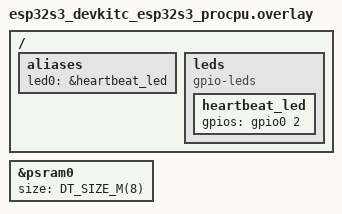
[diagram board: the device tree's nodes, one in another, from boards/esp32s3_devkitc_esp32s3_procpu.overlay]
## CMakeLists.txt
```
cmake_minimum_required(VERSION 3.20.0)

# Issue #71: pick up a local, untracked wifi_credentials.conf automatically
# if present (copied from wifi_credentials.conf.example - see
# firmware/README.md) - must happen before find_package(Zephyr ...) below,
# since that's where Kconfig fragments get collected. Never committed (see
# firmware/.gitignore); a clean checkout with no local file builds against
# this app's plain Kconfig defaults instead.
if(EXISTS "${CMAKE_CURRENT_SOURCE_DIR}/wifi_credentials.conf")
  set(EXTRA_CONF_FILE "${CMAKE_CURRENT_SOURCE_DIR}/wifi_credentials.conf")
endif()

find_package(Zephyr REQUIRED HINTS $ENV{ZEPHYR_BASE})
project(qc_bridge_firmware)

# ETL (https://github.com/ETLCPP/etl) - fixed-capacity containers, no heap
# allocation. See CODING_STANDARDS.md's Firmware/Memory & containers section.
include(FetchContent)
FetchContent_Declare(
  etl
  GIT_REPOSITORY https://github.com/ETLCPP/etl.git
  GIT_TAG        20.49.0
)
FetchContent_MakeAvailable(etl)

# miniz (https://github.com/richgel999/miniz) - issue #6's gzip detection
# for compressed message payloads, see ADR 0005. We want only its
# low-level inflate function (tinfl_decompress), not the deflate/zip-
# archive/zlib-wrapper code the rest of miniz also provides, and not its
# own CMakeLists.txt (which builds all of that as one target and calls
# project() in a way that doesn't nest cleanly inside a Zephyr app) - so
# this fetches the source tree only (FetchContent_Populate, not
# MakeAvailable: deliberately does not add_subdirectory it) and compiles
# just miniz_tinfl.c ourselves. The MINIZ_NO_* defines below strip the
# declarations miniz.h would otherwise pull in for the parts we're not
# compiling down to nothing. miniz_export.h (normally generated by
# miniz's own CMake via generate_export_header() for a shared-library
# build) is our own trivial stub - see third_party/miniz/miniz_export.h.
FetchContent_Declare(
  miniz
  GIT_REPOSITORY https://github.com/richgel999/miniz.git
  GIT_TAG        3.0.2
)
FetchContent_Populate(miniz)

# subsys/usb/host's own headers (usbh_class.h, usbh_desc.h, ...) aren't part
# of Zephyr's public API and aren't exported by its build - needed by
# usbh_shim.c, which is the only file that includes them. See that file.
zephyr_include_directories(${ZEPHYR_BASE}/subsys/usb/host)

target_sources(app PRIVATE
  src/Main.cpp
  src/usbh_shim.c
  ${miniz_SOURCE_DIR}/miniz_tinfl.c
)
target_include_directories(app PRIVATE
  ${miniz_SOURCE_DIR}
  ${CMAKE_CURRENT_SOURCE_DIR}/third_party/miniz
)
target_compile_definitions(app PRIVATE
  MINIZ_NO_STDIO
  MINIZ_NO_MALLOC
  MINIZ_NO_TIME
  # Not also defining MINIZ_NO_ARCHIVE_WRITING_APIS: miniz.h already
  # implies it from MINIZ_NO_DEFLATE_APIS (and MINIZ_NO_ARCHIVE_APIS
  # implies it a second time) - passing it here too just redefines the
  # same macro and trips a -Wmacro-redefined warning for no benefit.
  MINIZ_NO_DEFLATE_APIS
  MINIZ_NO_ARCHIVE_APIS
  MINIZ_NO_ZLIB_APIS
)
target_link_libraries(app PRIVATE etl::etl)

# Issue #71: links QcWifiWebTransport.hpp's HTTP_SERVICE_DEFINE(qcWebService,
# ...) to its own iterable-section linker fragment (sections-rom.ld) - see
# that file's own comment for why this is required, not optional, wiring.
zephyr_linker_sources(SECTIONS sections-rom.ld)
zephyr_linker_section(NAME http_resource_desc_qcWebService KVMA RAM_REGION GROUP RODATA_REGION)

# Issue #88 / ADR 0011: gzips web/ui into a generated header of static HTTP
# resources - see cmake/EmbedWebAssets.cmake for what this wires up.
# QcWifiWebTransport.hpp #includes the result unconditionally.
include(${CMAKE_CURRENT_SOURCE_DIR}/cmake/EmbedWebAssets.cmake)
qc_embed_web_assets(app)
```

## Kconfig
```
# Issue #71: Wi-Fi mode/credentials, chosen at build time. Mode itself
# reuses Zephyr's own generic choice (drivers/wifi/Kconfig,
# WIFI_USAGE_MODE_AP/STA) rather than inventing a parallel one - that choice
# is already what the NXP Wi-Fi driver keys its own SoftAP/DHCP-server
# defaults off (see ADR 0010). Real credentials belong in a local,
# untracked wifi_credentials.conf (see wifi_credentials.conf.example in
# this directory and firmware/README.md) - never in this file or in
# prj.conf, and never committed.

mainmenu "QC Remote Bridge Firmware"

config QC_WIFI_AP_SSID
	string "Soft AP SSID (CONFIG_WIFI_USAGE_MODE_AP)"
	default "QCRemote"
	depends on WIFI_USAGE_MODE_AP
	help
	  SSID the board advertises when running as its own access point.
	  Override in a local wifi_credentials.conf, not here.

config QC_WIFI_AP_PSK
	string "Soft AP WPA2 passphrase (CONFIG_WIFI_USAGE_MODE_AP)"
	default ""
	depends on WIFI_USAGE_MODE_AP
	help
	  WPA2-PSK passphrase for the board's own access point (8-63
	  characters). Left empty, the AP starts open (no password) - the
	  owner's decision for issue #71 is to set a real passphrase here via
	  a local wifi_credentials.conf whenever that's easy, rather than
	  defaulting to an open network. Never set a real passphrase in this
	  file or in prj.conf.

config QC_WIFI_AP_APP_DHCP_SERVER
	bool "Start the AP's address and DHCPv4 server in the app"
	default y if !WIFI_NXP
	depends on WIFI_USAGE_MODE_AP
	select NET_DHCPV4_SERVER
	help
	  The NXP Wi-Fi driver sets the SoftAP's address and runs its own
	  DHCPv4 server (CONFIG_NXP_WIFI_SOFTAP_*), and a second server would
	  collide with it (ADR 0010). Other drivers, such as the ESP32's,
	  leave both to the app - this turns that on, using the address
	  below.

config QC_WIFI_AP_IP_ADDRESS
	string "AP interface IPv4 address"
	default "192.168.4.1"
	depends on QC_WIFI_AP_APP_DHCP_SERVER
	help
	  Also the gateway. The DHCPv4 pool starts 10 addresses above it,
	  matching the 192.168.4.x range the NXP build uses.

config QC_WIFI_AP_NETMASK
	string "AP interface IPv4 netmask"
	default "255.255.255.0"
	depends on QC_WIFI_AP_APP_DHCP_SERVER

config QC_WIFI_STA_SSID
	string "Network SSID to join (CONFIG_WIFI_USAGE_MODE_STA)"
	default ""
	depends on WIFI_USAGE_MODE_STA
	help
	  SSID of the existing Wi-Fi network the board should join. Left
	  empty, the firmware logs a warning and skips connecting rather than
	  attempting to join a blank network - set this in a local
	  wifi_credentials.conf.

config QC_WIFI_STA_PSK
	string "Network WPA2 passphrase (CONFIG_WIFI_USAGE_MODE_STA)"
	default ""
	depends on WIFI_USAGE_MODE_STA
	help
	  WPA2-PSK passphrase for the network above. Set this in a local
	  wifi_credentials.conf - never here or in prj.conf.

config QC_USBH_FORCE_FULL_SPEED
	bool "Force the USB host port to Full Speed (test only)"
	depends on SOC_SERIES_RW6XX
	help
	  Sets PORTSC1.PFSC on the RW61x USB controller, so the port never
	  chirps up to High Speed and the attached device has to run at
	  12 Mbit/s. Lets the RW612 stand in for a Full Speed-only host
	  (ESP32-S3, MAX3421E) - see issue #76. The bit must be set before
	  the device attaches, so plug it in after boot. Leave off in normal
	  builds.

config QC_MESSAGE_CAPACITY
	int "Largest reassembled message, in bytes"
	default 131072
	help
	  Size of the HID reassembly buffer and the dispatcher mailbox, which
	  are kept equal. 128 KiB holds a worst-case fully-named preset folder
	  (ADR 0007). Boards with less internal RAM can lower it at the cost
	  of dropping messages larger than this.

config QC_WIFI_WEB_TICK_INTERVAL_MS
	int "WebSocket tick heartbeat interval, in milliseconds"
	default 5000
	help
	  How often QcWifiWebTransport sends a liveness-only "tick" envelope
	  (issue #75 / ADR 0011) to a connected WebSocket client when nothing
	  else was sent in that window. Without it, an idle rig and a
	  half-open socket after a Wi-Fi drop look identical - silence either
	  way. Matches web/poc/src/store.js's own assumed cadence (same ADR).

source "Kconfig.zephyr"
```

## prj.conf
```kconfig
# C++23, no exceptions/RTTI - see CODING_STANDARDS.md's Firmware section.
CONFIG_CPP=y
CONFIG_STD_CPP23=y
CONFIG_CPP_EXCEPTIONS=n
CONFIG_CPP_RTTI=n

# Zephyr defaults to MINIMAL_LIBCPP (no <span>, no STL) unless asked
# otherwise - not enough for this codebase (std::span, ETL, etc.). Selects
# GLIBCXX_LIBCPP given picolibc + the zephyr/gnu toolchain (lib/cpp/Kconfig).
CONFIG_REQUIRES_FULL_LIBCPP=y

# Heartbeat LED sanity check
CONFIG_GPIO=y

CONFIG_LOG=y
CONFIG_LOG_MODE_IMMEDIATE=y

# USB host [EXPERIMENTAL] - see ADR 0002 for the accepted risk. Enumerates
# the Quad Cortex Mini and claims its vendor HID interface (issue #3). Pulls
# in UHC_DRIVER; the NXP EHCI controller driver auto-selects itself once
# boards/frdm_rw612.overlay enables the usbh devicetree node.
CONFIG_USB_HOST_STACK=y

# Zephyr's own internal `usbh` thread (the same one that runs
# onProbe()/onReportIn(), see UsbHostClass.hpp) defaults to a 1024-byte
# stack (subsys/usb/host/Kconfig's CONFIG_USBH_STACK_SIZE) - a logging call
# added there during issue #8's hardware debugging (since removed, see
# QcSession.hpp's handleMessage()) overflowed it, confirmed via addr2line
# against the faulting PC/LR. With that logging gone for good,
# Zephyr's THREAD_ANALYZER measured this thread's real peak usage on
# hardware at 736 bytes; 1536 keeps that at just under half of budget
# rather than carrying forward the earlier emergency doubling to 2048 now
# that there's a real number to size against.
CONFIG_USBH_STACK_SIZE=1536

# So a future fault dump names the thread involved instead of "(unknown)" -
# this was off during issue #8's hardware debugging, which is also why
# Zephyr's own k_thread_name_set(&usbh_thread_data, "usbh") (usbh_core.c)
# and our own k_thread_name_set() calls (QcSession.hpp) weren't showing up
# in a fault dump either.
CONFIG_THREAD_NAME=y

# Issue #71: Wi-Fi + the web/WebSocket transport test - see ADR 0010.
# CONFIG_WIFI_USAGE_MODE_AP/STA itself (and real SSID/PSK) are chosen in a
# local, untracked wifi_credentials.conf (see wifi_credentials.conf.example
# and firmware/README.md) - everything below is the always-on plumbing
# that choice depends on either way, so it's committed. The Wi-Fi driver
# and its own settings are per board: boards/frdm_rw612.conf (NXP driver,
# which also runs the SoftAP's DHCPv4 server) and
# boards/esp32s3_devkitc_esp32s3_procpu.conf (ESP32 driver; the app runs
# the SoftAP's DHCPv4 server - CONFIG_QC_WIFI_AP_APP_DHCP_SERVER).
CONFIG_WIFI=y
CONFIG_ETH_DRIVER=n

CONFIG_NETWORKING=y
CONFIG_NET_L2_WIFI_MGMT=y
CONFIG_NET_IPV4=y
CONFIG_NET_TCP=y
CONFIG_NET_UDP=y
# STA mode: CONFIG_WIFI_STA_AUTO_DHCPV4 (subsys/net/l2/wifi/Kconfig,
# default y) starts the DHCPv4 client automatically once connected - no
# app code needed. AP mode: hardware testing on ac601b2 found that the NXP
# driver's own CONFIG_NXP_WIFI_SOFTAP_DHCP_SERVER DOES auto-start a
# DHCPv4 server for SoftAP - confirmed against drivers/wifi/nxp/src/
# nxp_wifi_drv.c's WLAN_REASON_UAP_SUCCESS handler, which this firmware's
# own now-removed app-layer DHCPv4 server start was conflicting with
# (-EALREADY, logged as nxp_wifi's "DHCP Server start failed" on
# hardware). CONFIG_NET_DHCPV4_SERVER itself is selected transitively by
# CONFIG_NXP_WIFI_SOFTAP_DHCP_SERVER on the RW612, and by the app's own
# CONFIG_QC_WIFI_AP_APP_DHCP_SERVER on other drivers (both only in AP
# mode) - no need to set it here, and station-only builds never pull it
# in since they have no DHCP server to run.
CONFIG_NET_DHCPV4=y
CONFIG_NET_IF_MAX_IPV4_COUNT=2
CONFIG_NET_CONFIG_AUTO_INIT=n
CONFIG_NET_CONNECTION_MANAGER=y
CONFIG_NET_MGMT=y
CONFIG_NET_MGMT_EVENT=y
# QcWifiWebTransport::onWifiEvent() reads net_mgmt_event_callback::info
# (e.g. the joining/leaving station's MAC in NET_EVENT_WIFI_AP_STA_*) -
# that field only exists when this is enabled.
CONFIG_NET_MGMT_EVENT_INFO=y
CONFIG_NET_MGMT_EVENT_QUEUE_SIZE=10
CONFIG_NET_MGMT_EVENT_STACK_SIZE=4608
# NET_PKT_{RX,TX}_COUNT and the net_buf counts are set with the TCP
# window budget further down - see CONFIG_NET_TCP_MAX_SEND_WINDOW_SIZE.
CONFIG_NET_SOCKETS_SERVICE_STACK_SIZE=4096
CONFIG_NET_TCP_WORKQ_STACK_SIZE=2048
CONFIG_SYSTEM_WORKQUEUE_STACK_SIZE=2048
CONFIG_MAIN_STACK_SIZE=4096

# Issue #71 hardware finding (26bfec1): root cause of the rx_q[0] stack-
# overflow usage fault on page load, in both AP and station mode, with or
# without a Quad Cortex attached - confirmed from source and from this
# build's own zephyr.elf, not our own code. Enabling Wi-Fi here pulls in
# CONFIG_PSA_CRYPTO + CONFIG_MCUX_ELS_PKC (the Wi-Fi driver's own security
# needs); subsys/net/ip/Kconfig.tcp's CONFIG_NET_TCP_ISN_RFC6528 ("depends
# on PSA_WANT_ALG_SHA_256", default y) silently flips on as a result - it's
# off on master today precisely because that dependency isn't met there.
# Once on, every newly-accepted TCP connection's initial sequence number
# (subsys/net/ip/tcp.c's tcp_isn_hash(), called inline during SYN
# processing on net_tc's own "rx_q[N]" thread - confirmed at net_tc.c:421)
# computes a real SHA-256 via psa_hash_compute() -> the hardware-backed
# ELS/PKC driver -> NXP's mcuxCl hash library, instead of master's shallow
# sys_rand32_get() fallback. Measured on this build's zephyr.elf (gcc
# prologue push+sub sp, same per-frame method as every other stack-margin
# table in this firmware): tcp_isn_hash (56 B) -> psa_hash_compute (tail
# call, net 0 B) -> psa_driver_wrapper_hash_compute (40 B) ->
# els_pkc_transparent_hash_compute (32 B) ->
# mcuxClPsaDriver_psa_driver_wrapper_hash_compute (296 B) ->
# mcuxClHash_compute (120 B) -> mcuxClHashModes_Els_oneShot_Sha2 (152 B) ->
# its _FullBlocks/_ProcessData/_Truncated callee (108-240 B depending on
# input length) -> mcuxClHashModes_Els_oneShot_Sha2_Padding (120 B) ->
# mcuxClMemory_copy (80 B, where the fault PC/LR from both hardware runs
# land - 0x18006dba/0x18004db5 on this build) = ~1136 B for this chain
# alone, on top of whatever net_tc/IP/TCP processing it took to reach SYN
# handling in the first place - loading the page's first new TCP
# connection (the fetch and/or the WebSocket upgrade) is what triggers it,
# which is why an empty catalog and no USB device still crash identically.
# CONFIG_NET_RX_STACK_SIZE's own default (1500 B, matching the "1504"
# thread_analyzer budget on hardware) was sized for the pre-Wi-Fi,
# non-cryptographic ISN path and was never going to survive this chain.
# Doubled to a round 3072 B - leaves real headroom (the chain above is the
# deepest path this thread takes; ordinary packet forwarding is far
# shallower) without the much larger jump a "disable the fancy ISN
# instead" workaround would have avoided needing. Unverified on hardware -
# needs a fresh flash to confirm (see firmware/README.md).
CONFIG_NET_RX_STACK_SIZE=3072

# Zephyr's HTTP server [EXPERIMENTAL] + its websocket upgrade path -
# issue #71's "minimal page and a WebSocket" requirement
# (QcWifiWebTransport.hpp). CONFIG_HTTP_SERVER_WEBSOCKET selects
# WEBSOCKET_CLIENT (the same library backs both directions of the
# protocol).
#
# WEBSOCKET_MAX_CONTEXTS=2, matching QcWifiWebTransport's own
# kMaxWsContexts - issue #99 / ADR 0012: one live page, and the newest one
# wins, so a new page's upgrade has to succeed while the old page is still
# connected; the old one is then closed with 4001. Zephyr hands this
# resource's one static data_buffer (g_qcWsDataBuffer) to
# websocket_register() on every upgrade, so both contexts share it (issue
# #75, ADR 0010) - safe only because the transport's worker thread reads
# just the live socket, and starts reading the new one after closing the
# old. See kMaxWsContexts' own comment.
CONFIG_HTTP_SERVER=y
CONFIG_HTTP_SERVER_WEBSOCKET=y
# Eight, after 13 regressed the board (PR #92, third round). 6 for a
# browser's own per-host connection cap + 1 for a transient WebSocket
# upgrade (which holds a slot only until
# handle_http1_to_websocket_upgrade() hands the socket off) + 1 spare.
#
# 13 was sized for two browsers' *parked* connections and made hardware
# strictly worse: Chrome went from loading fine to hanging, with one
# module eventually RST mid-response after 45s. Parked idle connections
# cost a slot but no network buffers; connections being *served* cost
# both, and the server accepts up to this many, so this number also caps
# how many sends can be in flight at once - which is what the TCP window
# budget below has to cover. Accepting more connections than the link's
# buffer budget can serve turns a queue into a stall. Two browsers at
# once is handled by recycling parked slots quickly (the inactivity
# timeout below) rather than by holding a slot open for each.
CONFIG_HTTP_SERVER_MAX_CLIENTS=8

# Halved from Zephyr's default of 10 (and matching its own
# HTTP_SERVER_VERSION_3 default), so a parked keep-alive connection
# recycles its slot in 5s rather than 10. Zephyr's server never sends
# Connection: close, and the timer is armed in init_client_ctx() and
# restarted only on a data event, so an *idle* connection otherwise holds
# its slot for the full timeout after its last request - which is how a
# second browser (or the same one reloading) got locked out behind the
# first. Deliberately not cut further: at 2s,
# tests/wifi_web_http's test_two_assets_on_one_keep_alive_connection
# starts failing, because the server drops the connection between the
# page request and the next asset request on it - a real regression for
# keep-alive reuse, not a test artifact.
CONFIG_HTTP_SERVER_CLIENT_INACTIVITY_TIMEOUT=5

# PR #92's third round, and the one that only shows up on real hardware.
# Symptom: with the two fixes below already in place, a page load served
# its first few files in 11-30ms each and then stalled on the parallel
# wave - three modules finally arriving at ~20s and the fourth getting
# "200 OK" and then an RST mid-response at 45s, with 0.1 kB transferred,
# so the import graph never resolved. It got *worse* when
# HTTP_SERVER_MAX_CLIENTS went from 6 to 13, which is the clue: the
# binding resource scales with the number of connections being served at
# once, not with slots.
#
# Root cause, from subsys/net/ip/tcp.c's own window initialisation:
#
#   tcp_tx_window = (CONFIG_NET_BUF_TX_COUNT * CONFIG_NET_BUF_DATA_SIZE) / 3
#
# when CONFIG_NET_TCP_MAX_SEND_WINDOW_SIZE is 0 (its default), and the
# same shape for tcp_rx_window out of the RX pool. That is **one third of
# the entire pool, applied per connection** - so any more than three
# concurrently-sending connections oversubscribes the pool *by
# construction*, no matter how big the pool is. Raising the buffer counts
# alone cannot fix it; it raises the per-connection window by exactly the
# same factor. The window has to be pinned.
#
# With this board's previous NET_BUF_TX_COUNT=36 (Zephyr's own
# NET_PKT_LARGE_DEFAULTS value, on because CONFIG_WIFI is set) and
# NET_BUF_DATA_SIZE=128, that was a 1536-byte window per connection
# against a 4608-byte pool: 2x oversubscribed at 6 clients, 4.3x at 13.
# TCP holds a segment's buffers until it is ACKed, so on a real Wi-Fi
# link (the owner measured 25-150ms RTT) they stay held for a whole round
# trip and the pool genuinely runs dry - the send then stalls, and the
# connection ends in a reset rather than an error the client can retry.
#
# This is exactly why tests/wifi_web_http passes off-board while the
# board fails: over loopback the RTT is microseconds, so a buffer is
# allocated, sent, ACKed and freed before anything else needs it, and the
# oversubscription never bites. That difference - not buffer counts, not
# the poll limits - is what the loopback suite cannot model, and it is
# worth remembering before trusting it about anything throughput-related.
#
# The budget, written out so it can be checked rather than tuned:
#   - 2048 B window per connection: at a 100ms RTT that is ~20 KB/s, so
#     the largest asset (vendor/lit.js, 7053 B gzipped) takes ~0.35s, and
#     a whole 6-file wave ~2s even if the server serialises them (it has
#     one thread, so it does).
#   - 8 connections x 2048 B = 16384 B of TX data in flight, worst case.
#   - 160 TX buffers x 128 B = 20480 B, i.e. 1.25x that budget.
#   - RX is deliberately smaller (96 x 128 B = 12288 B): the inbound
#     direction only carries request headers (~600 B each) and ACKs, so
#     the advertised receive window is headroom this firmware never
#     fills, not a throughput constraint.
#   - NET_PKT_{TX,RX}_COUNT 24: a 2048 B window is ~2 segments at this
#     MTU, so 8 connections need ~16 pending sends plus ACKs.
CONFIG_NET_TCP_MAX_SEND_WINDOW_SIZE=2048
CONFIG_NET_TCP_MAX_RECV_WINDOW_SIZE=2048
CONFIG_NET_BUF_TX_COUNT=160
CONFIG_NET_BUF_RX_COUNT=96
CONFIG_NET_PKT_TX_COUNT=24
CONFIG_NET_PKT_RX_COUNT=24

# PR #92's hardware blocker (issue #88), the original root cause. Zephyr's
# HTTP server watches all of its descriptors in a single zsock_poll()
# call - 1 eventfd + one listening socket + CONFIG_HTTP_SERVER_MAX_CLIENTS
# accepted sockets (subsys/net/lib/http/http_server_core.c's
# HTTP_SERVER_SOCK_COUNT and the zsock_poll() in http_server_run()). Each
# *active* descriptor in that call needs one entry in
# zvfs_poll_internal()'s own `struct k_poll_event
# poll_events[CONFIG_ZVFS_POLL_MAX]` (lib/os/zvfs/zvfs_poll.c), and
# zsock_poll_prepare_ctx() returns -ENOMEM the moment it runs out
# (subsys/net/lib/sockets/sockets_inet.c). CONFIG_ZVFS_POLL_MAX's own
# default is 3 (lib/os/zvfs/Kconfig; the larger "6 if
# WIFI_NM_WPA_SUPPLICANT" default does not apply - this build uses the
# NXP driver, confirmed against its own .config), which is eventfd +
# listener + exactly *one* client. So a second simultaneous connection
# made poll() fail, and http_server_run() treats a poll() failure as
# fatal: close_all_sockets() drops every live connection *and* the
# listening socket, then the thread re-inits after
# CONFIG_HTTP_SERVER_RESTART_DELAY (1s). That is precisely the owner's
# first curl result on hardware - sequential requests all 200, two or
# more in parallel mostly reset (56) / empty reply (52) / refused (7),
# the last being connects that land inside the 1s restart window. It
# stayed hidden because the old inline page only ever made sequential
# requests.
#
# Needed: 1 + 1 + CONFIG_HTTP_SERVER_MAX_CLIENTS = 10. This is a *stack*
# array in whichever thread calls poll(), ~20 bytes per entry on
# Cortex-M - it costs no static RAM. Kept exactly at the requirement
# rather than padded: CONFIG_HTTP_SERVER_STACK_SIZE is only 3072 bytes,
# and this array lives on it.
CONFIG_ZVFS_POLL_MAX=10

# The pools a parallel page load draws from, which the defaults left with
# no room either. Every TCP connection takes one net_context and
# registers one net_conn 5-tuple handler (subsys/net/ip/tcp.c's
# tcp_conn_new()), and when either pool is empty the SYN gets an RST
# straight back (net_tcp_reply_rst() on the tcp_conn_new() failure path) -
# the same curl 56 as above, from a different cause. Needed: 1 listening
# socket + 8 accepted + 1 for the DHCPv4 client = 10, against defaults of
# 6 and 8, with nothing left for a closed connection still sitting in
# TIME_WAIT (CONFIG_NET_TCP_TIME_WAIT_DELAY is 1500ms, and a page reload
# closes and reopens a whole browser's worth at once). 14/18 leaves that
# headroom.
#
# CONFIG_ZVFS_OPEN_MAX is deliberately not set: it defaults to the sum of
# the subsystems' own requirements, and ZVFS_OPEN_ADD_SIZE_NET follows
# NET_MAX_CONTEXTS (subsys/net/ip/Kconfig), so the file-descriptor table
# grows with the line below to 14 + 1 - comfortably past the 12 the
# server needs (eventfd + listener + 8 clients + up to two WebSocket fds).
CONFIG_NET_MAX_CONTEXTS=14
CONFIG_NET_MAX_CONN=18
CONFIG_WEBSOCKET_MAX_CONTEXTS=2
# Issue #71's 5068403 smoke test: without this, a *dynamic* resource's
# response line is "HTTP/1.1 200\r\n" - subsys/net/lib/http/
# http_server_http1.c's RESPONSE_TEMPLATE_DYNAMIC_PART1 is
# "HTTP/1.1 %d%s%s\r\n" and both %s are empty when this is off, so even
# the space after the status code is missing. RFC 9112 section 4 makes
# that space mandatory (the reason phrase itself may be empty), so the
# only response in this firmware that a browser rejected was also the
# only one not sending a well-formed status line - the static page
# resource sends a hardcoded "HTTP/1.1 200 OK". Zephyr's own help text
# for this option says the absence "does not affect protocol compliance
# or client behavior", which is what the generated line above
# contradicts. Costs a small string table.
```

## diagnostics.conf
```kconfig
# Opt-in diagnostics for the network/HTTP path (issue #88, PR #92).
#
# NOT part of any normal build. Pass it explicitly, alongside the
# credentials file that firmware/app/CMakeLists.txt picks up on its own:
#
#   west build -b frdm_rw612 firmware/app -d build-diag --pristine \
#     -- -DEXTRA_CONF_FILE="diagnostics.conf"
#
# (If you keep a local wifi_credentials.conf, list both, semicolon
# separated: -DEXTRA_CONF_FILE="wifi_credentials.conf;diagnostics.conf".)
#
# Why this exists: PR #92's connection-concurrency bugs were all
# *resource budget* bugs - poll slots, client slots, net_contexts, and
# finally the TCP window against the net_buf pools - and two rounds of
# them were diagnosed from source and a loopback test, then found wrong
# on hardware. A loopback suite cannot model a 25-150ms RTT, which is
# exactly what makes a buffer budget bite. This fragment makes the board
# report the numbers instead, so the next round is measured.
#
# What to capture: flash this build, load the page, then grab the serial
# console. See firmware/README.md's "Parallel connections" section.

# Per-pool allocation counts and high-water marks for the net_buf pools,
# which is what the TCP window budget in prj.conf is sized against. With
# this on, a pool that ran dry shows up as a failed-allocation count
# rather than as a mysterious stall.
CONFIG_NET_BUF_POOL_USAGE=y

# TCP-level counters: retransmits, drops, connection drops. A starved
# pool shows up here as retransmits and segment drops climbing during a
# page load.
CONFIG_NET_STATISTICS=y
CONFIG_NET_STATISTICS_TCP=y
CONFIG_NET_STATISTICS_PERIODIC_OUTPUT=y
CONFIG_NET_STATISTICS_USER_API=y

# The net shell is how the two above get read out on demand ("net stats",
# "net mem", "net conn") rather than only on the periodic timer.
CONFIG_SHELL=y
CONFIG_NET_SHELL=y

# Stack headroom for every thread, so a silent overflow is ruled in or
# out rather than guessed at - zvfs_poll_internal() puts a
# k_poll_event[CONFIG_ZVFS_POLL_MAX] array on the stack of whichever
# thread calls poll(), and the HTTP server thread's own stack is only
# CONFIG_HTTP_SERVER_STACK_SIZE (3072 B). THREAD_ANALYZER is the same
# tool that produced the usbh and rx_q stack numbers quoted in prj.conf.
CONFIG_THREAD_ANALYZER=y
CONFIG_THREAD_ANALYZER_USE_PRINTK=y
CONFIG_THREAD_ANALYZER_AUTO=y
CONFIG_THREAD_ANALYZER_AUTO_INTERVAL=15
CONFIG_THREAD_NAME=y
CONFIG_INIT_STACKS=y

# A stack overflow should fault loudly and name the thread, not corrupt a
# neighbour silently.
CONFIG_STACK_SENTINEL=y

# The HTTP server's own debug logging: which client slot each connection
# lands in, when one is released, and "No free slot found" if the slots
# really are the constraint.
CONFIG_NET_LOG=y
CONFIG_NET_HTTP_SERVER_LOG_LEVEL_DBG=y
```

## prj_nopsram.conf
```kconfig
# Base config for -DFILE_SUFFIX=nopsram (ESP32-S3 module without PSRAM,
# issue #76/#71): Zephyr's FILE_SUFFIX support substitutes this file for
# prj.conf entirely rather than merging with it (cmake/modules/
# configuration_files.cmake's zephyr_file(CONF_FILES ... NAMES "prj.conf"
# SUFFIX ...)), so it's a full base, not a delta. Kept identical to
# prj.conf's own common section (CPP/GPIO/LOG/USB host) below - the only
# difference is what's absent: this file never assigns CONFIG_WIFI,
# CONFIG_NETWORKING, CONFIG_HTTP_SERVER, or anything under them. A nopsram
# module can't fit Wi-Fi alongside the protocol buffers in internal RAM
# (see boards/esp32s3_devkitc_esp32s3_procpu_nopsram.conf), and assigning
# those symbols here anyway - then relying on the board .conf to force them
# back off - used to produce ~20 "assigned but unsatisfied dependency"
# Kconfig warnings per build for values that could never apply. Main.cpp
# leaves the web transport out entirely once CONFIG_WIFI is off.

# C++23, no exceptions/RTTI - see CODING_STANDARDS.md's Firmware section.
CONFIG_CPP=y
CONFIG_STD_CPP23=y
CONFIG_CPP_EXCEPTIONS=n
CONFIG_CPP_RTTI=n

# Zephyr defaults to MINIMAL_LIBCPP (no <span>, no STL) unless asked
# otherwise - not enough for this codebase (std::span, ETL, etc.). Selects
# GLIBCXX_LIBCPP given picolibc + the zephyr/gnu toolchain (lib/cpp/Kconfig).
CONFIG_REQUIRES_FULL_LIBCPP=y

# Heartbeat LED sanity check
CONFIG_GPIO=y

CONFIG_LOG=y
CONFIG_LOG_MODE_IMMEDIATE=y

# USB host [EXPERIMENTAL] - see ADR 0002 for the accepted risk. Enumerates
# the Quad Cortex Mini and claims its vendor HID interface (issue #3). Pulls
# in UHC_DRIVER; the NXP EHCI controller driver auto-selects itself once
# boards/frdm_rw612.overlay enables the usbh devicetree node.
CONFIG_USB_HOST_STACK=y

# Zephyr's own internal `usbh` thread (the same one that runs
# onProbe()/onReportIn(), see UsbHostClass.hpp) defaults to a 1024-byte
# stack (subsys/usb/host/Kconfig's CONFIG_USBH_STACK_SIZE) - a logging call
# added there during issue #8's hardware debugging (since removed, see
# QcSession.hpp's handleMessage()) overflowed it, confirmed via addr2line
# against the faulting PC/LR. With that logging gone for good,
# Zephyr's THREAD_ANALYZER measured this thread's real peak usage on
# hardware at 736 bytes; 1536 keeps that at just under half of budget
# rather than carrying forward the earlier emergency doubling to 2048 now
# that there's a real number to size against.
CONFIG_USBH_STACK_SIZE=1536

# So a future fault dump names the thread involved instead of "(unknown)" -
# this was off during issue #8's hardware debugging, which is also why
# Zephyr's own k_thread_name_set(&usbh_thread_data, "usbh") (usbh_core.c)
# and our own k_thread_name_set() calls (QcSession.hpp) weren't showing up
# in a fault dump either.
CONFIG_THREAD_NAME=y
```

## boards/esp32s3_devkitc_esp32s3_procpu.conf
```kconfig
# 8 MB octal PSRAM (WROOM-1-N8R8/N16R8; RevA's N16R8 has the same). With
# Wi-Fi (issue #71) the app's static data doesn't fit the S3's internal RAM
# by ~160 KB, so all of libapp.a's .bss - the 128 KiB message buffers (ADR
# 0007), the catalog, the web transport's JSON buffers - moves to PSRAM.
# That includes the app's own thread stacks (K_KERNEL_STACK_MEMBERs inside
# those objects); fine as long as nothing runs from them with the flash
# cache disabled. For a module without PSRAM, see the _nopsram files.
CONFIG_ESP_SPIRAM=y
CONFIG_SPIRAM_MODE_OCT=y
CONFIG_ESP_SPIRAM_BSS_RELOC_LIBS_AND_OBJS="libapp.a"
```

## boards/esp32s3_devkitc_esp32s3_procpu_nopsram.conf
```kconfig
# ESP32-S3 module without PSRAM (WROOM-1-N8/N16), -DFILE_SUFFIX=nopsram.
# USB host and the protocol only: Wi-Fi plus the web transport (issue #71)
# overflow the S3's internal RAM by ~160 KB without PSRAM, so this build's
# base config is prj_nopsram.conf, not prj.conf - it never assigns
# CONFIG_WIFI/CONFIG_NETWORKING/CONFIG_HTTP_SERVER in the first place (see
# that file's own comment). Main.cpp leaves the web transport out when
# CONFIG_WIFI is off.

# The two 128 KiB message buffers (ADR 0007) don't fit internal RAM either.
# 64 KiB still holds every message measured on the owner's unit (largest
# 22667 bytes, a RecallPreset push); only a near-full, fully-named folder
# would overflow.
CONFIG_QC_MESSAGE_CAPACITY=65536
```

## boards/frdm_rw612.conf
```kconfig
# Issue #71: the RW612's Wi-Fi driver and its SoftAP settings, split out of
# prj.conf (issue #76) so the same app also builds for the ESP32-S3.
# Modeled on Zephyr's own samples/net/wifi/apsta_mode sample + its boards/frdm_rw612.conf
# (CONFIG_WIFI_NXP/CONFIG_NXP_RW610 - RW610 and RW612 share the same
# wifi/BLE/802.15.4 radio silicon, Kconfig only distinguishes by that
# radio, not the MCU's own flash/pin variant), the only sample confirmed
# (via Zephyr's own test plan, samples/net/wifi/shell/tests.yaml) to build
# for this board. CONFIG_NXP_WIFI_SOFTAP_SUPPORT and its own DHCPv4 server
# (CONFIG_NXP_WIFI_SOFTAP_DHCP_SERVER) default on for this SoC series once
# WIFI_USAGE_MODE_AP/STA_AP is selected - confirmed on hardware (ac601b2)
# to be real, not just a default worth trusting blindly: this firmware
# used to *also* start its own app-layer DHCPv4 server on the same SoftAP
# interface, which collided with the driver's own (-EALREADY, "DHCP
# Server start failed"). That app-layer server is gone (see
# QcWifiWebTransport::startAccessPoint()'s own comment); the IP range
# below only overrides the driver's own default (192.168.10.x) to keep
# this firmware's documented 192.168.4.x range.
CONFIG_NXP_WIFI_SOFTAP_IP_ADDRESS="192.168.4.1"
CONFIG_NXP_WIFI_SOFTAP_IP_GATEWAY="192.168.4.1"
CONFIG_NXP_WIFI_SOFTAP_IP_MASK="255.255.255.0"
CONFIG_NXP_WIFI_SOFTAP_IP_BASE="192.168.4.11"
CONFIG_WIFI_NXP=y
CONFIG_NXP_RW610=y
```

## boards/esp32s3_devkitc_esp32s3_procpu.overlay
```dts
/*
 * ESP32-S3-DevKitC-1 with an 8 MB octal-PSRAM module (WROOM-1-N8R8/N16R8,
 * the same PSRAM as RevA's N16R8) - issue #76, ADR 0009. For a module
 * without PSRAM (N8/N16), build with -DFILE_SUFFIX=nopsram instead, which
 * picks up esp32s3_devkitc_esp32s3_procpu_nopsram.{overlay,conf}.
 *
 * USB host: the board devicetree already labels the S3's OTG controller
 * zephyr_uhc0 and enables it, so nothing to change here. Its D-/D+ are fixed
 * at GPIO19/GPIO20 (header J3 pins 20/19), not routed through pinctrl. The
 * board's native micro-USB port has no VBUS output (it only powers the
 * board), so the Quad Cortex is wired from the header instead - see
 * firmware/README.md.
 *
 * Heartbeat LED: Main.cpp blinks led0, but this board only has an addressable
 * RGB LED (GPIO48), which a plain GPIO toggle can't drive. GPIO2 (J3 pin 5) is
 * unused here - put an LED + resistor on it to see the heartbeat, or ignore.
 */

/ {
	aliases {
		led0 = &heartbeat_led;
	};

	leds {
		compatible = "gpio-leds";

		heartbeat_led: heartbeat_led {
			gpios = <&gpio0 2 GPIO_ACTIVE_HIGH>;
		};
	};
};

&psram0 {
	size = <DT_SIZE_M(8)>;
};
```

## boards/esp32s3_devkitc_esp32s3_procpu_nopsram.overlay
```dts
/*
 * ESP32-S3-DevKitC-1 with a module *without* PSRAM (WROOM-1-N8/N16), selected
 * with -DFILE_SUFFIX=nopsram - issue #76. Wi-Fi is off in the matching .conf:
 * it doesn't fit internal RAM alongside the protocol buffers. Otherwise the
 * same as esp32s3_devkitc_esp32s3_procpu.overlay (see there for the USB and
 * LED notes), minus the PSRAM node.
 */

/ {
	aliases {
		led0 = &heartbeat_led;
	};

	leds {
		compatible = "gpio-leds";

		heartbeat_led: heartbeat_led {
			gpios = <&gpio0 2 GPIO_ACTIVE_HIGH>;
		};
	};
};
```

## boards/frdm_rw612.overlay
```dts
/*
 * frdm_rw612's own board devicetree enables the RW612's single USB-OTG
 * peripheral in device mode (zephyr_udc0) by default. We need host mode to
 * enumerate the Quad Cortex Mini, so flip it: disable the device-mode node
 * and enable the host-mode one instead. Both compatibles map to the same
 * physical register range (see nxp_rw6xx_common.dtsi) - they're mutually
 * exclusive, not additive.
 */

&usb_otg {
	status = "disabled";
};

zephyr_uhc0: &usbh {
	status = "okay";
};
```

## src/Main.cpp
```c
#include <zephyr/drivers/gpio.h>
#include <zephyr/kernel.h>
#include <zephyr/logging/log.h>

LOG_MODULE_REGISTER(main, LOG_LEVEL_INF);

#include "QcHidBridge.hpp"
// Off on a board config without Wi-Fi (e.g. an ESP32-S3 module with no
// PSRAM, issue #76) - the USB bridge then runs on its own.
#if defined(CONFIG_WIFI)
#include "QcWifiWebTransport.hpp"
#endif

namespace qcbridge {

// Bring-up sanity check for the frdm_rw612 toolchain/build (issue #2) - not
// part of the actual bridge firmware. Confirms the board boots, GPIO and
// logging work, and the app links against a real C++23 toolchain.
class HeartbeatLed {
public:
    explicit HeartbeatLed(const gpio_dt_spec& spec) : spec_(spec) {}

    bool init() const {
        if (!gpio_is_ready_dt(&spec_)) {
            return false;
        }
        return gpio_pin_configure_dt(&spec_, GPIO_OUTPUT_ACTIVE) == 0;
    }

    void toggle() const { gpio_pin_toggle_dt(&spec_); }

private:
    gpio_dt_spec spec_;
};

}  // namespace qcbridge

namespace {
const gpio_dt_spec kLedSpec = GPIO_DT_SPEC_GET(DT_ALIAS(led0), gpios);
const auto kBlinkInterval = K_MSEC(500);
qcbridge::QcHidBridge g_qcHidBridge;
#if defined(CONFIG_WIFI)
qcbridge::QcWifiWebTransport g_qcWifiWebTransport;
#endif
}  // namespace

int main() {
    const qcbridge::HeartbeatLed led(kLedSpec);

    if (!led.init()) {
        LOG_ERR("Failed to initialize heartbeat LED");
        return 0;
    }

    LOG_INF("QC Bridge firmware skeleton up (C++%ld)", static_cast<long>(__cplusplus));

    // Issue #71: registered before start() so it's in place before any
    // device connects and a File listing can finish - see QcSession.hpp's
    // own comment on addTransport()'s ordering requirement. QcHidBridge/
    // QcSession never include QcWifiWebTransport.hpp themselves (see that
    // header's own comment) - this is the one place Wi-Fi/HTTP and the USB
    // bridge meet.
#if defined(CONFIG_WIFI)
    g_qcHidBridge.session().addTransport(g_qcWifiWebTransport);
    g_qcWifiWebTransport.setSwitcher(g_qcHidBridge.session());
    g_qcWifiWebTransport.start();
#endif

    if (g_qcHidBridge.start() != 0) {
        LOG_ERR("USB host bridge failed to start");
    } else {
        LOG_INF("USB host enabled, waiting for Quad Cortex Mini");
    }

    while (true) {
        led.toggle();
        k_sleep(kBlinkInterval);
    }
}
```

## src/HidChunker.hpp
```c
#pragma once

#include <cstddef>
#include <cstdint>
#include <span>

#include "HidReassembler.hpp"

namespace qcbridge {

// Splits a logical message into a sequence of 129-byte HID reports, per
// qc-mcp's framing (see HidReassembler.hpp for the byte layout this
// mirrors). Call next() repeatedly until done() - each call fills exactly
// one report.
class HidChunker {
public:
    HidChunker(std::span<const uint8_t> message, uint8_t reportId)
        : message_(message), reportId_(reportId) {}

    bool done() const { return emittedAtLeastOne_ && offset_ >= message_.size(); }

    // Fills `outReport` (must be exactly kHidReportSize bytes) with the next
    // report. Returns false if done() was already true (nothing written).
    bool next(std::span<uint8_t> outReport) {
        if (outReport.size() != kHidReportSize || done()) {
            return false;
        }

        const size_t remaining = message_.size() - offset_;
        const size_t chunkLen =
            remaining < kHidMaxPayloadPerReport ? remaining : kHidMaxPayloadPerReport;
        const bool isFirst = offset_ == 0;
        const bool isLast = offset_ + chunkLen >= message_.size();

        HidReportFlag flag;
        if (isFirst && isLast) {
            flag = HidReportFlag::Single;
        } else if (isFirst) {
            flag = HidReportFlag::First;
        } else if (isLast) {
            flag = HidReportFlag::Last;
        } else {
            flag = HidReportFlag::Middle;
        }

        outReport[0] = reportId_;
        outReport[1] = static_cast<uint8_t>(chunkLen);
        outReport[2] = static_cast<uint8_t>(flag);
        for (size_t i = 0; i < kHidMaxPayloadPerReport; ++i) {
            outReport[kHidHeaderSize + i] = i < chunkLen ? message_[offset_ + i] : uint8_t{0};
        }

        offset_ += chunkLen;
        emittedAtLeastOne_ = true;
        return true;
    }

private:
    std::span<const uint8_t> message_;
    uint8_t reportId_;
    size_t offset_ = 0;
    bool emittedAtLeastOne_ = false;
};

}  // namespace qcbridge
```

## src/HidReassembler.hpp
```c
#pragma once

#include <cstddef>
#include <cstdint>
#include <span>

#include <etl/vector.h>

namespace qcbridge {

// qc-mcp's HID report framing (see PROTOCOL.md / transport.py):
//
//   byte 0 : report id (0x01 in / 0x02 out)
//   byte 1 : chunk length (0-126 payload bytes in this report)
//   byte 2 : flags (FIRST/MIDDLE/LAST/SINGLE)
//   byte 3+: payload, zero-padded to kHidReportSize
//
// kHidReportSize is 129, not 128: transport.py's own REPORT_SIZE (128) is the
// *body* (chunk length + flags + payload) and excludes the report-id byte,
// which it prepends separately (message_to_reports() allocates
// `1 + REPORT_SIZE`). kHidReportSize here is the total wire size, report id
// included, so it's REPORT_SIZE + 1.
inline constexpr size_t kHidReportSize = 129;
inline constexpr size_t kHidHeaderSize = 3;
inline constexpr size_t kHidMaxPayloadPerReport = kHidReportSize - kHidHeaderSize;

enum class HidReportFlag : uint8_t {
    Middle = 0x00,
    First = 0x40,
    Last = 0x80,
    Single = 0xC0,
};

// Reassembles a sequence of 128-byte HID reports into one logical message.
//
// Capacity is the largest reassembled message this instance can hold - see
// issue #33 for the actual sizing exercise. Not yet instantiated anywhere
// in the real transport (that's the still-open part of #4 - see usbh_shim.c);
// this file and its Ztest suite (tests/hid_framing) stand on their own.
//
// Issue #33's measurement step: a message whose true size exceeds Capacity
// no longer aborts the moment that's detected (the original behavior silently
// dropped the rest of the message, which meant every MIDDLE/LAST report that
// followed for it had no preceding FIRST and miscounted as a second,
// unrelated failure - see Status::Malformed below and the real hardware
// numbers in firmware/README.md's #60/#61 section: overflow=31 but
// malformed=2850, almost all of which were exactly this). Instead it keeps
// consuming reports - without growing the stored body past Capacity - until
// the LAST/SINGLE report completes it, tracking the message's true total
// size via overflowSize() below.
template <size_t Capacity>
class HidReassembler {
public:
    enum class Status {
        InProgress,  // fed a FIRST or MIDDLE report, message isn't complete yet
        Complete,    // fed a LAST or SINGLE report - message() is valid now
        Overflow,    // fed a LAST or SINGLE report, but the true size exceeded
                     // Capacity at some point during assembly - message() is
                     // NOT valid; overflowSize()/overflowTrailer() are instead
        Malformed,   // bad chunk length, or a MIDDLE/LAST with no preceding FIRST
    };

    // Feeds one report, exactly kHidReportSize bytes.
    Status feed(std::span<const uint8_t> report) {
        if (report.size() != kHidReportSize) {
            return fail();
        }

        const uint8_t chunkLen = report[1];
        const uint8_t flags = report[2];

        if (chunkLen > kHidMaxPayloadPerReport) {
            return fail();
        }

        const bool isFirst = flags == static_cast<uint8_t>(HidReportFlag::First) ||
                             flags == static_cast<uint8_t>(HidReportFlag::Single);
        const bool isMiddle = flags == static_cast<uint8_t>(HidReportFlag::Middle);
        const bool isLast = flags == static_cast<uint8_t>(HidReportFlag::Last) ||
                            flags == static_cast<uint8_t>(HidReportFlag::Single);

        if (!isFirst && !isMiddle && !isLast) {
            return fail();
        }

        if (isFirst) {
            buffer_.clear();
            overflowing_ = false;
            overflowSize_ = 0;
        } else if (buffer_.empty() && !overflowing_) {
            // A MIDDLE/LAST with no preceding FIRST, and not a continuation
            // of a message already overflowing (see below): out of order,
            // or we missed the FIRST. Nothing sane to reassemble.
            return fail();
        }

        const auto chunk = report.subspan(kHidHeaderSize, chunkLen);

        if (overflowing_) {
            // Already past Capacity for this message - keep tracking its
            // true size, but don't touch buffer_ (it was cleared, and stays
            // empty, the moment overflow began below).
            overflowSize_ += chunkLen;
            if (isLast) {
                overflowing_ = false;
                return Status::Overflow;
            }
            return Status::InProgress;
        }

        if (buffer_.size() + chunkLen > Capacity) {
            // Transition into overflow: the true size so far (whatever was
            // already in buffer_, plus this chunk) is tracked from here on
            // instead of the body itself.
            overflowing_ = true;
            overflowSize_ = buffer_.size() + chunkLen;
            buffer_.clear();
            if (isLast) {
                overflowing_ = false;
                return Status::Overflow;
            }
            return Status::InProgress;
        }

        buffer_.insert(buffer_.end(), chunk.begin(), chunk.end());

        return isLast ? Status::Complete : Status::InProgress;
    }

    // Valid only right after feed() returns Complete.
    std::span<const uint8_t> message() const { return {buffer_.data(), buffer_.size()}; }

    // Valid only right after feed() returns Overflow: the message's true
    // total size (report headers excluded), which Capacity could not hold.
    size_t overflowSize() const { return overflowSize_; }

private:
    Status fail() {
        buffer_.clear();
        overflowing_ = false;
        overflowSize_ = 0;
        return Status::Malformed;
    }

    etl::vector<uint8_t, Capacity> buffer_;
    bool overflowing_ = false;
    size_t overflowSize_ = 0;
};

}  // namespace qcbridge
```

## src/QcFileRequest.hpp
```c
#pragma once

#include <cstdint>

#include <etl/vector.h>

#include "QcHandshakeMessages.hpp"
#include "QcMessage.hpp"
#include "QcProtobuf.hpp"

namespace qcbridge {

// FileMessage's CortexMessageType.Enum id (qc-mcp's protocol.py COMMANDS
// map). Kept separate from QcHandshakeMessages.hpp's command ids since File
// isn't part of the handshake.
inline constexpr uint16_t kCommandFile = 4;

// FileMessage READ: 1=action, 2=request_id, 11=omit_factory_content
// (verified against qc-mcp's own descriptor set, qc_descriptors-4.1.pb,
// same way issue #5's Tier 2 messages were). A READ with no `type`/`folder`
// set asks for the device's whole catalog (presets, IRs, captures) as a
// stream of File UPDATE messages - mirrors qc-mcp's own
// transport.py::list_directory(), except qc-mcp itself never sets
// `omit_factory_content`.
//
// Always true (issue #33): a hardware measurement (commit 219cf6e, see
// docs/adr/0007-file-reassembly-buffer-sizing.md) found this is the option
// that actually shrinks the catalog - from 568 File messages/~716KB down
// to 20/~30KB on the owner's unit - while still naming every one of their
// 48 user/cloud presets (`My Presets`, `Practice`, `cloud-0-1`); a sibling
// option, `short_listing`, measured no effect at all. What gets left out
// is factory-bundled plugin-library content (e.g. "Archetype: Cory Wong
// X"'s own presets) - still fully present on the device, just not listed
// here. A `short_listing`-style toggle isn't exposed as a parameter
// anymore: this is the one shape the firmware ever sends.
inline void encodeFileRead(HandshakeMessageBuffer& out, uint64_t requestId) {
    etl::vector<uint8_t, kHandshakeMessageCapacity> proto;
    writeEnum(proto, 1, static_cast<int>(MessageAction::Read));
    writeUInt64(proto, 2, requestId);
    writeBool(proto, 11, true);
    encodeMessage(out, kCommandFile, {proto.data(), proto.size()});
}

}  // namespace qcbridge
```
